# STM32F401CBU3 register map
File version: 1.0
Registers are 32-bit, access not given, reset 0x0 unless marked. A register's access mark holds for its fields unless they carry their own. Offsets are from the block's base; [hi:lo] are bit positions; {n}, {i} and the like mark numbered series.

## GPIOA
Base 0x40020000
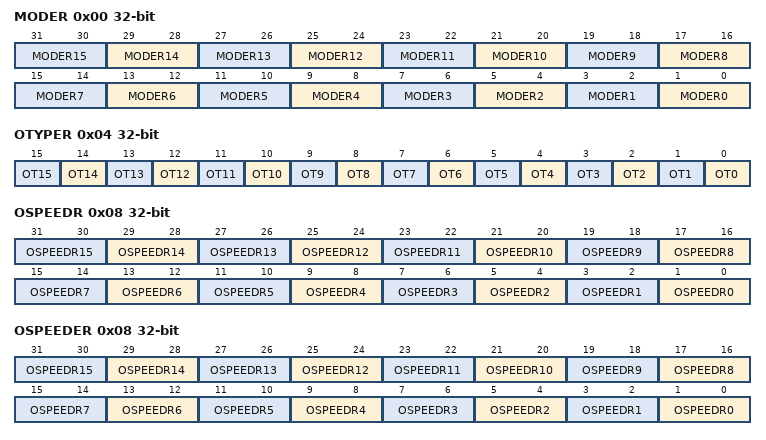
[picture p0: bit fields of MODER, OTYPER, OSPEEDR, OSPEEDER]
0x00 MODER
  [2n+1:2n] MODER{n} (n=0..15)
0x04 OTYPER
  [n] OT{n} (n=0..15)
0x08 OSPEEDR
  [2n+1:2n] OSPEEDR{n} (n=0..15)
0x08 OSPEEDER
  [2n+1:2n] OSPEEDR{n} (n=0..15)
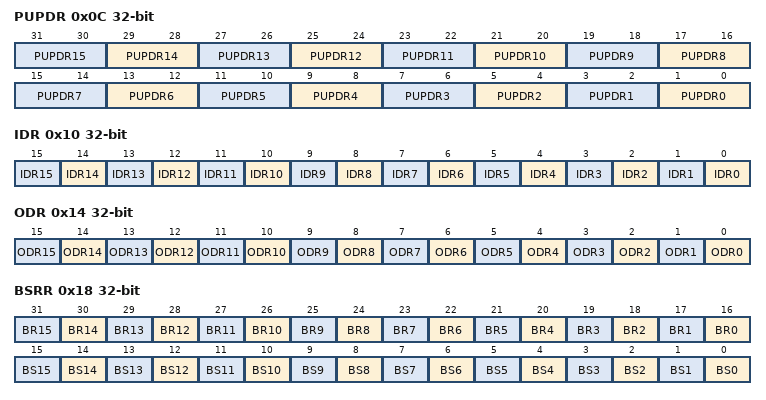
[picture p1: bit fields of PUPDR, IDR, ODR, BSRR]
0x0C PUPDR
  [2n+1:2n] PUPDR{n} (n=0..15)
0x10 IDR
  [n] IDR{n} (n=0..15)
0x14 ODR
  [n] ODR{n} (n=0..15)
0x18 BSRR
  [n+16] BR{n} (n=0..15), [n] BS{n} (n=0..15)
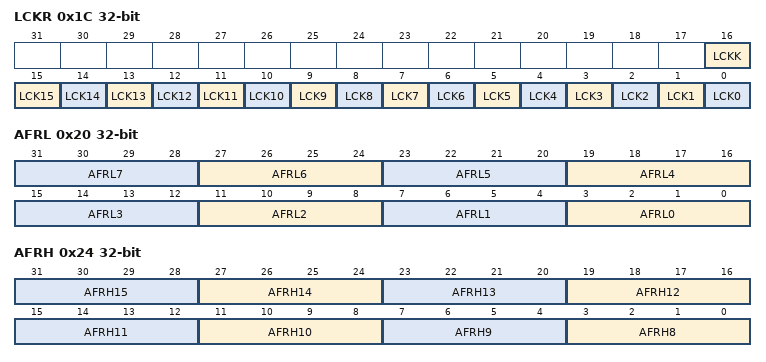
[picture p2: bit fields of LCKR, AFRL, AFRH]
0x1C LCKR
  [16] LCKK, [n] LCK{n} (n=0..15)
0x20 AFRL
  [4n+3:4n] AFRL{n} (n=0..7)
0x24 AFRH
  [4n-29:4n-32] AFRH{n} (n=8..15)

## GPIOB
Base 0x40020400
Registers as GPIOA, without OSPEEDER.

## GPIOC
Base 0x40020800
Registers as GPIOA, without OSPEEDER.

## GPIOD
Base 0x40020C00
Registers as GPIOA, without OSPEEDER.

## GPIOE
Base 0x40021000
Registers as GPIOA, without OSPEEDER.

## GPIOH
Base 0x40021C00
Registers as GPIOA, without OSPEEDER.

## CRC
Base 0x40023000
0x00 DR
  [30:0] DATA
0x04 IDR
  [7:0] DATA
0x08 CR
  [0] RESET

## RCC
Base 0x40023800
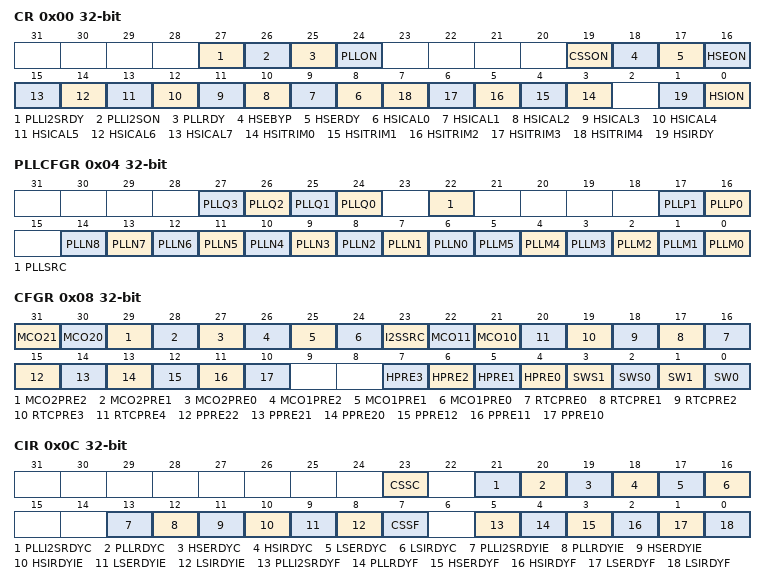
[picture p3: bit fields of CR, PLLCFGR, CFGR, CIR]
0x00 CR
  [27] PLLI2SRDY, [26] PLLI2SON, [25] PLLRDY, [24] PLLON, [19] CSSON, [18] HSEBYP, [17] HSERDY, [16] HSEON, [n+8] HSICAL{n} (n=0..7), [n+3] HSITRIM{n} (n=0..4), [1] HSIRDY, [0] HSION
0x04 PLLCFGR
  [n+24] PLLQ{n} (n=0..3), [22] PLLSRC, [17] PLLP1, [16] PLLP0, [n+6] PLLN{n} (n=0..8), [n] PLLM{n} (n=0..5)
0x08 CFGR
  [31] MCO21, [30] MCO20, [29] MCO2PRE2, [28] MCO2PRE1, [27] MCO2PRE0, [26] MCO1PRE2, [25] MCO1PRE1, [24] MCO1PRE0, [23] I2SSRC, [22] MCO11, [21] MCO10, [n+16] RTCPRE{n} (n=0..4), [15] PPRE22, [14] PPRE21, [13] PPRE20, [12] PPRE12, [11] PPRE11, [10] PPRE10, [n+4] HPRE{n} (n=0..3), [3] SWS1, [2] SWS0, [1] SW1, [0] SW0
0x0C CIR
  [23] CSSC, [21] PLLI2SRDYC, [20] PLLRDYC, [19] HSERDYC, [18] HSIRDYC, [17] LSERDYC, [16] LSIRDYC, [13] PLLI2SRDYIE, [12] PLLRDYIE, [11] HSERDYIE, [10] HSIRDYIE, [9] LSERDYIE, [8] LSIRDYIE, [7] CSSF, [5] PLLI2SRDYF, [4] PLLRDYF, [3] HSERDYF, [2] HSIRDYF, [1] LSERDYF, [0] LSIRDYF
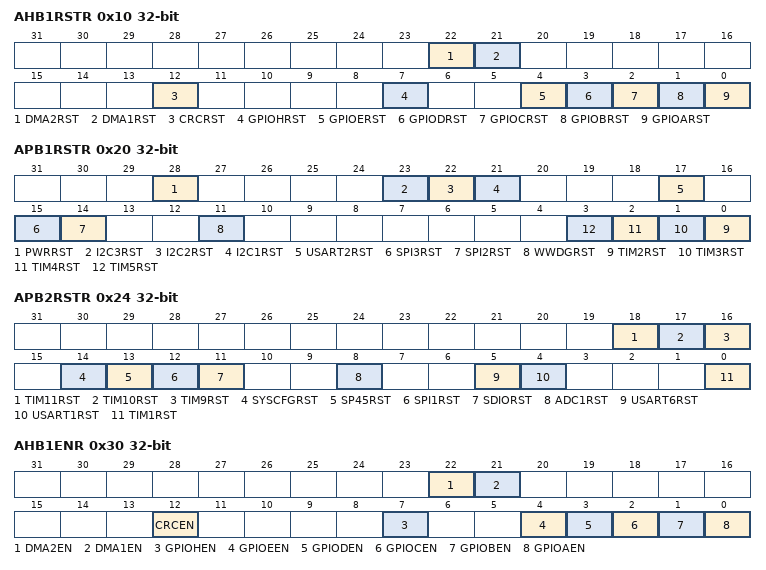
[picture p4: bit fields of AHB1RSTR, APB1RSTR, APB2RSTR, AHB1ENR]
0x10 AHB1RSTR
  [22] DMA2RST, [21] DMA1RST, [12] CRCRST, [7] GPIOHRST, [4] GPIOERST, [3] GPIODRST, [2] GPIOCRST, [1] GPIOBRST, [0] GPIOARST
0x14 AHB2RSTR
  [7] OTGFSRST
0x20 APB1RSTR
  [28] PWRRST, [23] I2C3RST, [22] I2C2RST, [21] I2C1RST, [17] USART2RST, [15] SPI3RST, [14] SPI2RST, [11] WWDGRST, [n-2] TIM{n}RST (n=2..5)
0x24 APB2RSTR
  [18] TIM11RST, [17] TIM10RST, [16] TIM9RST, [14] SYSCFGRST, [13] SP45RST, [12] SPI1RST, [11] SDIORST, [8] ADC1RST, [5] USART6RST, [4] USART1RST, [0] TIM1RST
0x30 AHB1ENR
  [22] DMA2EN, [21] DMA1EN, [12] CRCEN, [7] GPIOHEN, [4] GPIOEEN, [3] GPIODEN, [2] GPIOCEN, [1] GPIOBEN, [0] GPIOAEN
0x34 AHB2ENR
  [7] OTGFSEN
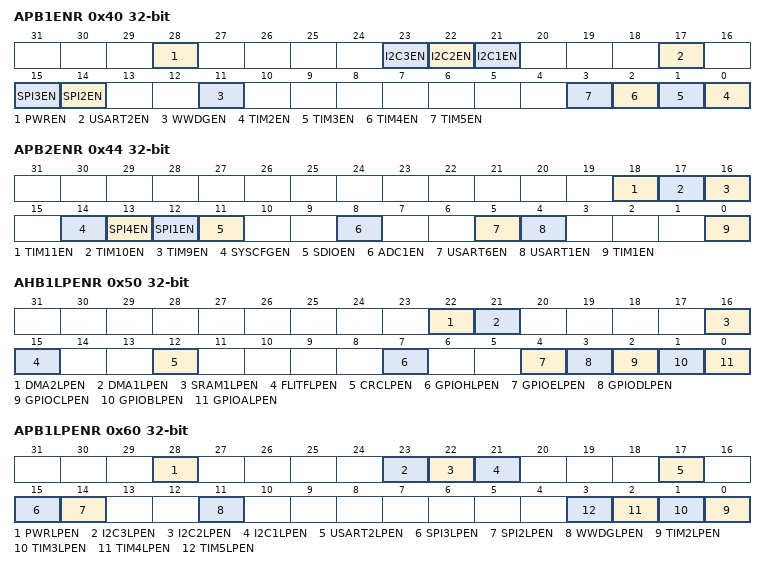
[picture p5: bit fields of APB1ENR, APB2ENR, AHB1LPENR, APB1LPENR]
0x40 APB1ENR
  [28] PWREN, [23] I2C3EN, [22] I2C2EN, [21] I2C1EN, [17] USART2EN, [15] SPI3EN, [14] SPI2EN, [11] WWDGEN, [n-2] TIM{n}EN (n=2..5)
0x44 APB2ENR
  [18] TIM11EN, [17] TIM10EN, [16] TIM9EN, [14] SYSCFGEN, [13] SPI4EN, [12] SPI1EN, [11] SDIOEN, [8] ADC1EN, [5] USART6EN, [4] USART1EN, [0] TIM1EN
0x50 AHB1LPENR
  [22] DMA2LPEN, [21] DMA1LPEN, [16] SRAM1LPEN, [15] FLITFLPEN, [12] CRCLPEN, [7] GPIOHLPEN, [4] GPIOELPEN, [3] GPIODLPEN, [2] GPIOCLPEN, [1] GPIOBLPEN, [0] GPIOALPEN
0x54 AHB2LPENR
  [7] OTGFSLPEN
0x60 APB1LPENR
  [28] PWRLPEN, [23] I2C3LPEN, [22] I2C2LPEN, [21] I2C1LPEN, [17] USART2LPEN, [15] SPI3LPEN, [14] SPI2LPEN, [11] WWDGLPEN, [n-2] TIM{n}LPEN (n=2..5)
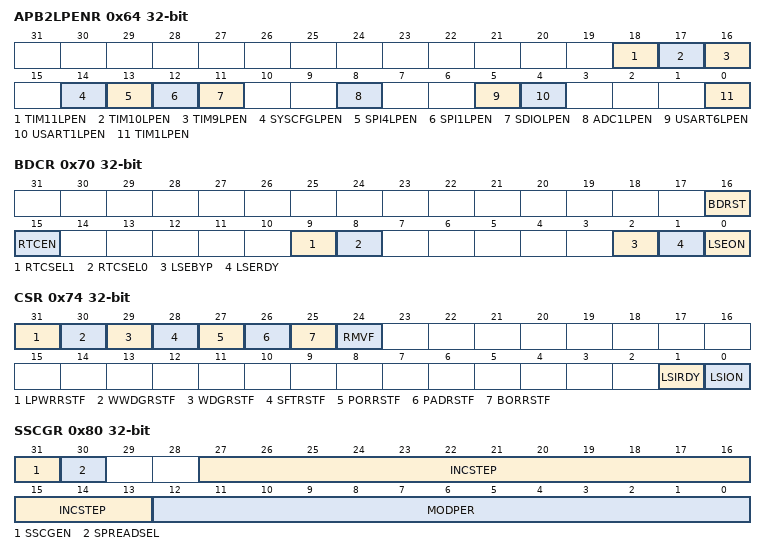
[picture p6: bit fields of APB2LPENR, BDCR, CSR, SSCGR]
0x64 APB2LPENR
  [18] TIM11LPEN, [17] TIM10LPEN, [16] TIM9LPEN, [14] SYSCFGLPEN, [13] SPI4LPEN, [12] SPI1LPEN, [11] SDIOLPEN, [8] ADC1LPEN, [5] USART6LPEN, [4] USART1LPEN, [0] TIM1LPEN
0x70 BDCR
  [16] BDRST, [15] RTCEN, [9] RTCSEL1, [8] RTCSEL0, [2] LSEBYP, [1] LSERDY, [0] LSEON
0x74 CSR
  [31] LPWRRSTF, [30] WWDGRSTF, [29] WDGRSTF, [28] SFTRSTF, [27] PORRSTF, [26] PADRSTF, [25] BORRSTF, [24] RMVF, [1] LSIRDY, [0] LSION
0x80 SSCGR
  [31] SSCGEN, [30] SPREADSEL, [27:13] INCSTEP, [12:0] MODPER
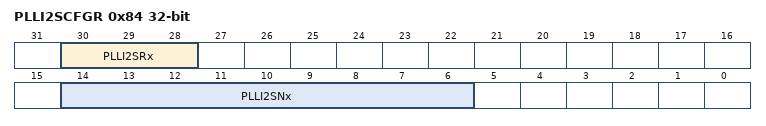
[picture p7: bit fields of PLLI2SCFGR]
0x84 PLLI2SCFGR
  [30:28] PLLI2SRx, [14:6] PLLI2SNx
0x8C DCKCFGR
  [24] TIMPRE

## FLASH
Base 0x40023C00
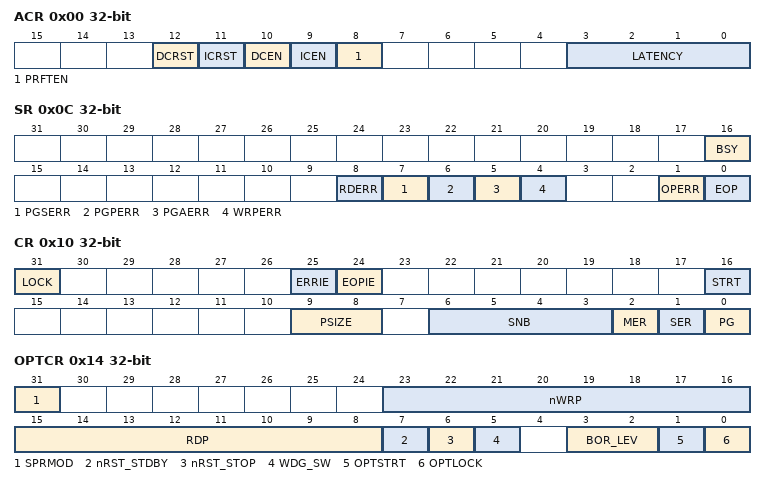
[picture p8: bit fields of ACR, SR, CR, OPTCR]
0x00 ACR
  [12] DCRST, [11] ICRST, [10] DCEN, [9] ICEN, [8] PRFTEN, [3:0] LATENCY
0x04 KEYR
  [31:0] KEY
0x08 OPTKEYR
0x0C SR
  [16] BSY, [8] RDERR, [7] PGSERR, [6] PGPERR, [5] PGAERR, [4] WRPERR, [1] OPERR, [0] EOP
0x10 CR
  [31] LOCK, [25] ERRIE, [24] EOPIE, [16] STRT, [9:8] PSIZE, [6:3] SNB, [2] MER, [1] SER, [0] PG
0x14 OPTCR
  [31] SPRMOD, [23:16] nWRP, [15:8] RDP, [7] nRST_STDBY, [6] nRST_STOP, [5] WDG_SW, [3:2] BOR_LEV, [1] OPTSTRT, [0] OPTLOCK

## DMA1
Base 0x40026000
Same registers: DMA2 0x40026400
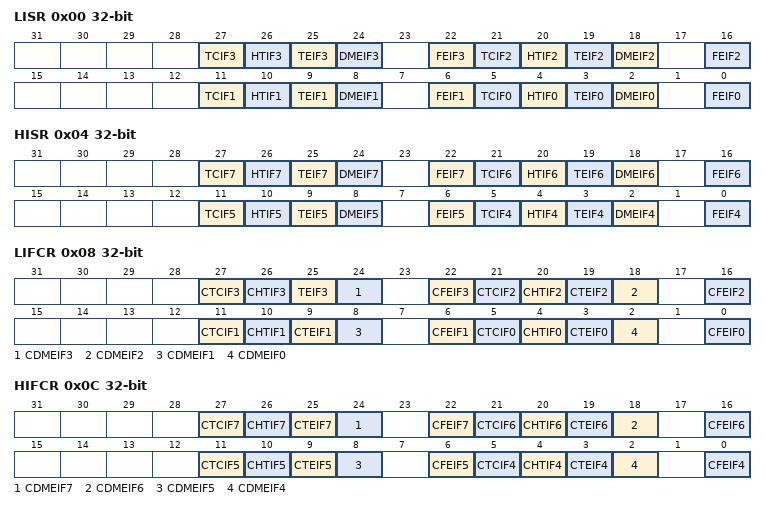
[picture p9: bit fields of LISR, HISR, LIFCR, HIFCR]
0x00 LISR
  [27] TCIF3, [26] HTIF3, [25] TEIF3, [24] DMEIF3, [22] FEIF3, [21] TCIF2, [20] HTIF2, [19] TEIF2, [18] DMEIF2, [16] FEIF2, [11] TCIF1, [10] HTIF1, [9] TEIF1, [8] DMEIF1, [6] FEIF1, [5] TCIF0, [4] HTIF0, [3] TEIF0, [2] DMEIF0, [0] FEIF0
0x04 HISR
  [27] TCIF7, [26] HTIF7, [25] TEIF7, [24] DMEIF7, [22] FEIF7, [21] TCIF6, [20] HTIF6, [19] TEIF6, [18] DMEIF6, [16] FEIF6, [11] TCIF5, [10] HTIF5, [9] TEIF5, [8] DMEIF5, [6] FEIF5, [5] TCIF4, [4] HTIF4, [3] TEIF4, [2] DMEIF4, [0] FEIF4
0x08 LIFCR
  [27] CTCIF3, [26] CHTIF3, [25] TEIF3, [24] CDMEIF3, [22] CFEIF3, [21] CTCIF2, [20] CHTIF2, [19] CTEIF2, [18] CDMEIF2, [16] CFEIF2, [11] CTCIF1, [10] CHTIF1, [9] CTEIF1, [8] CDMEIF1, [6] CFEIF1, [5] CTCIF0, [4] CHTIF0, [3] CTEIF0, [2] CDMEIF0, [0] CFEIF0
0x0C HIFCR
  [27] CTCIF7, [26] CHTIF7, [25] CTEIF7, [24] CDMEIF7, [22] CFEIF7, [21] CTCIF6, [20] CHTIF6, [19] CTEIF6, [18] CDMEIF6, [16] CFEIF6, [11] CTCIF5, [10] CHTIF5, [9] CTEIF5, [8] CDMEIF5, [6] CFEIF5, [5] CTCIF4, [4] CHTIF4, [3] CTEIF4, [2] CDMEIF4, [0] CFEIF4
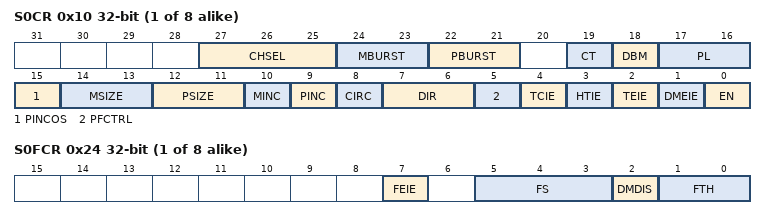
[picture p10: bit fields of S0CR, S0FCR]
{0x10+0x18*i} S{i}CR (i=0..7)
  [27:25] CHSEL, [24:23] MBURST, [22:21] PBURST, [19] CT, [18] DBM, [17:16] PL, [15] PINCOS, [14:13] MSIZE, [12:11] PSIZE, [10] MINC, [9] PINC, [8] CIRC, [7:6] DIR, [5] PFCTRL, [4] TCIE, [3] HTIE, [2] TEIE, [1] DMEIE, [0] EN
{0x14+0x18*i} S{i}NDTR (i=0..7)
  [15:0] NDT
{0x18+0x18*i} S{i}PAR (i=0..7)
  [31:0] PA
{0x1C+0x18*i} S{i}M0AR (i=0..7)
  [31:0] M0A
{0x20+0x18*i} S{i}M1AR (i=0..7)
  [31:0] M1A
{0x24+0x18*i} S{i}FCR (i=0..7)
  [7] FEIE, [5:3] FS, [2] DMDIS, [1:0] FTH
